# STM32WBA6M register map
File version: 1.0
CPU: CM33 r0p1, little endian, MPU, FPU, 4 interrupt priority bits
Registers are 32-bit, read-write, reset 0x0 unless marked. A register's access mark holds for its fields unless they carry their own. Offsets are from the block's base; [hi:lo] are bit positions; {n}, {i} and the like mark numbered series.

## GPIOB — GPIOB address block description
Base 0x42020400
Same registers: SEC_GPIOB 0x52020400
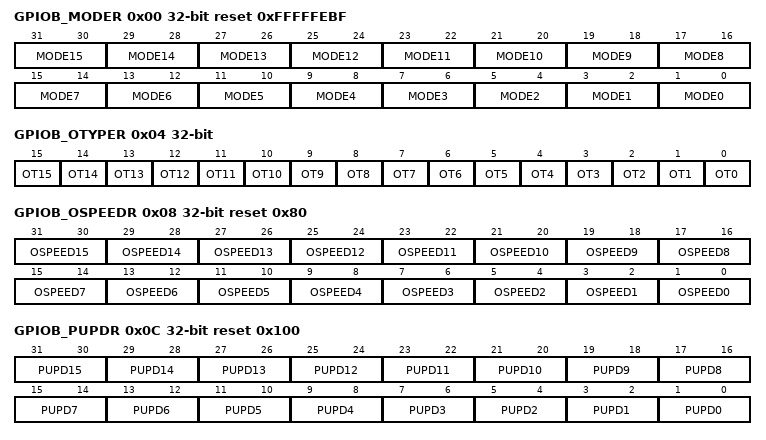
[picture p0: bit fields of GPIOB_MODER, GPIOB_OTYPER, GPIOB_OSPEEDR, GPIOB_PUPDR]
0x00 GPIOB_MODER reset 0xFFFFFEBF — GPIO port B mode register
  [31:30] MODE15 — Port configuration I/O pin 15
    0=Input mode; 1=General purpose output mode; 2=Alternate function mode; 3=Analog mode (reset state)
  [2n+1:2n] MODE{n} (n=0..14) — Port configuration I/O pin {n}
0x04 GPIOB_OTYPER — GPIO port B output type register
  [all] fields
    0=Output push-pull (reset state); 1=Output open-drain
  [n] OT{n} (n=0..15) — Port configuration I/O pin y
0x08 GPIOB_OSPEEDR reset 0x80 — GPIO port B output speed register
  [31:30] OSPEED15 — Port configuration I/O pin 15
    0=Low speed; 1=Medium speed; 2=High speed
  [2n+1:2n] OSPEED{n} (n=0..14) — Port configuration I/O pin {n}
0x0C GPIOB_PUPDR reset 0x100 — GPIO port B pull-up/pull-down register
  [31:30] PUPD15 — Port configuration I/O pin 15
    0=No pull-up, pull-down; 1=Pull-up; 2=Pull-down
  [2n+1:2n] PUPD{n} (n=0..14) — Port configuration I/O pin {n}
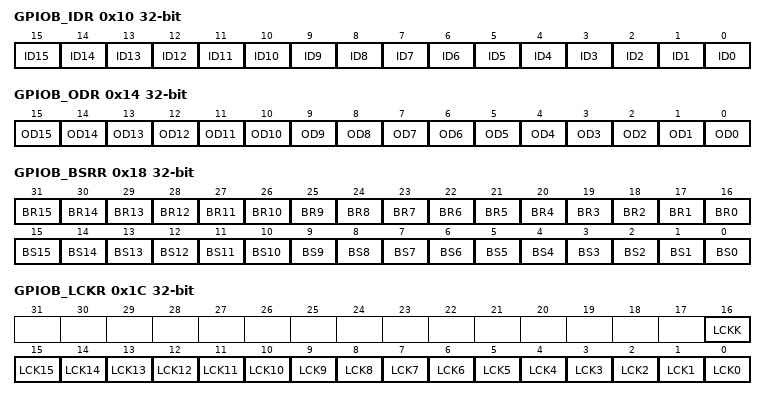
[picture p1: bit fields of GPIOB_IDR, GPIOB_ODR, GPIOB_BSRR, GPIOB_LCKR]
0x10 GPIOB_IDR ro (reset mask 0xFFFF0000) — GPIO port B input data register
  [n] ID{n} (n=0..15) — Port input data I/O pin y
0x14 GPIOB_ODR — GPIO port B output data register
  [n] OD{n} (n=0..15) — Port output data I/O pin y
0x18 GPIOB_BSRR wo — GPIO port B bit set/reset register
  [n+16] BR{n} (n=0..15) — Port reset I/O pin y
    0=No action on the corresponding ODy bit; 1=Resets the corresponding ODy bit
  [n] BS{n} (n=0..15) — Port set I/O pin y
    0=No action on the corresponding ODy bit; 1=Sets the corresponding ODy bit
0x1C GPIOB_LCKR — GPIO port B configuration lock register
  [16] LCKK — Lock key
    0=Port configuration lock key not active; 1=Port configuration lock key active
  [n] LCK{n} (n=0..15) — Port lock I/O pin y
    0=Port configuration not locked; 1=Port configuration locked
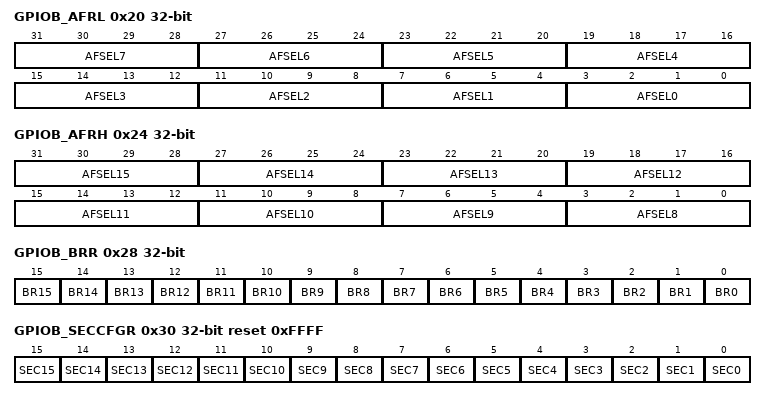
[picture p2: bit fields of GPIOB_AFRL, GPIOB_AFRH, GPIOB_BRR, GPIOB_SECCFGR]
0x20 GPIOB_AFRL — GPIO port B alternate function low register
  [31:28] AFSEL7 — Alternate function selection for port I/O pin 7
    {v}=AF{v} (v=0..15)
  [4n+3:4n] AFSEL{n} (n=0..6) — Alternate function selection for port I/O pin {n}
0x24 GPIOB_AFRH — GPIO port B alternate function high register
  [31:28] AFSEL15 — Alternate function selection for port I/O pin 15
    {v}=AF{v} (v=0..15)
  [4n-29:4n-32] AFSEL{n} (n=8..14) — Alternate function selection for port I/O pin {n}
0x28 GPIOB_BRR wo — GPIO port B bit reset register
  [all] fields
    0=No action on the corresponding ODy bit; 1=Reset the corresponding ODy bit
  [n] BR{n} (n=0..15) — Port reset I/O pin y
0x30 GPIOB_SECCFGR reset 0xFFFF — GPIO port B secure configuration register
  [all] fields
    0=The I/O pin is nonsecure; 1=The I/O pin is secure
  [n] SEC{n} (n=0..15) — I/O pin of port secure bit enable y

## GPIOC — GPIOC address block description
Base 0x42020800
Same registers: SEC_GPIOC 0x52020800
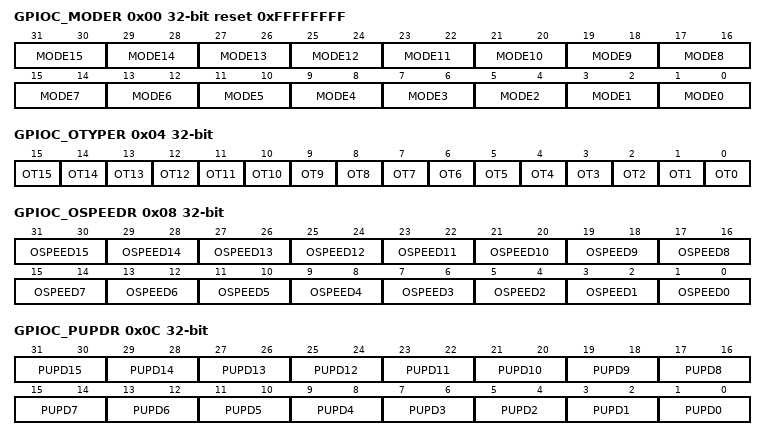
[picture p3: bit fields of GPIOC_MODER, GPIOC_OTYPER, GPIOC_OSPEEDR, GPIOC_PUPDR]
0x00 GPIOC_MODER reset 0xFFFFFFFF — GPIO port C mode register
  [31:30] MODE15 — Port configuration I/O pin 15
    0=Input mode; 1=General purpose output mode; 2=Alternate function mode; 3=Analog mode (reset state)
  [2n+1:2n] MODE{n} (n=0..14) — Port configuration I/O pin {n}
0x04 GPIOC_OTYPER — GPIO port C output type register
  [all] fields
    0=Output push-pull (reset state); 1=Output open-drain
  [n] OT{n} (n=0..15) — Port configuration I/O pin y
0x08 GPIOC_OSPEEDR — GPIO port C output speed register
  [31:30] OSPEED15 — Port configuration I/O pin 15
    0=Low speed; 1=Medium speed; 2=High speed
  [2n+1:2n] OSPEED{n} (n=0..14) — Port configuration I/O pin {n}
0x0C GPIOC_PUPDR — GPIO port C pull-up/pull-down register
  [31:30] PUPD15 — Port configuration I/O pin 15
    0=No pull-up, pull-down; 1=Pull-up; 2=Pull-down
  [2n+1:2n] PUPD{n} (n=0..14) — Port configuration I/O pin {n}
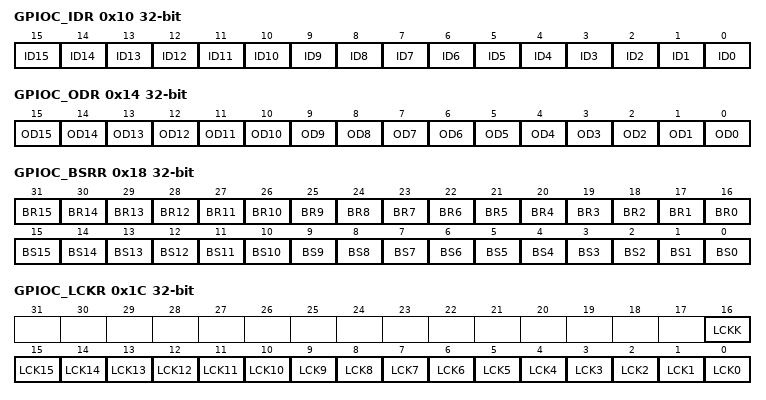
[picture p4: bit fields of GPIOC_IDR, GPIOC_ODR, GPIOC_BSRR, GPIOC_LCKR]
0x10 GPIOC_IDR ro (reset mask 0xFFFF0000) — GPIO port C input data register
  [n] ID{n} (n=0..15) — Port input data I/O pin y
0x14 GPIOC_ODR — GPIO port C output data register
  [n] OD{n} (n=0..15) — Port output data I/O pin y
0x18 GPIOC_BSRR wo — GPIO port C bit set/reset register
  [n+16] BR{n} (n=0..15) — Port reset I/O pin y
    0=No action on the corresponding ODy bit; 1=Resets the corresponding ODy bit
  [n] BS{n} (n=0..15) — Port set I/O pin y
    0=No action on the corresponding ODy bit; 1=Sets the corresponding ODy bit
0x1C GPIOC_LCKR — GPIO port C configuration lock register
  [16] LCKK — Lock key
    0=Port configuration lock key not active; 1=Port configuration lock key active
  [n] LCK{n} (n=0..15) — Port lock I/O pin y
    0=Port configuration not locked; 1=Port configuration locked
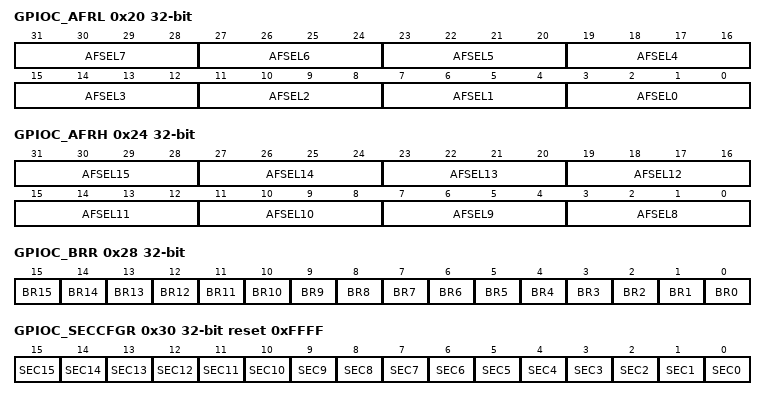
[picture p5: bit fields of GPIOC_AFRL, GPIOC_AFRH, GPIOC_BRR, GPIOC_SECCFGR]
0x20 GPIOC_AFRL — GPIO port C alternate function low register
  [31:28] AFSEL7 — Alternate function selection for port I/O pin 7
    {v}=AF{v} (v=0..15)
  [4n+3:4n] AFSEL{n} (n=0..6) — Alternate function selection for port I/O pin {n}
0x24 GPIOC_AFRH — GPIO port C alternate function high register
  [31:28] AFSEL15 — Alternate function selection for port I/O pin 15
    {v}=AF{v} (v=0..15)
  [4n-29:4n-32] AFSEL{n} (n=8..14) — Alternate function selection for port I/O pin {n}
0x28 GPIOC_BRR wo — GPIO port C bit reset register
  [all] fields
    0=No action on the corresponding ODy bit; 1=Reset the corresponding ODy bit
  [n] BR{n} (n=0..15) — Port reset I/O pin y
0x30 GPIOC_SECCFGR reset 0xFFFF — GPIO port C secure configuration register
  [all] fields
    0=The I/O pin is nonsecure; 1=The I/O pin is secure
  [n] SEC{n} (n=0..15) — I/O pin of port secure bit enable y

## Notices in the file
Copyright (c) 2025 STMicroelectronics.
SPDX-License-Identifier: Apache-2.0
Licensed under the Apache License, Version 2.0 (the "License");
you may not use this file except in compliance with the License.
You may obtain a copy of the License at
http://www.apache.org/licenses/LICENSE-2.0
Unless required by applicable law or agreed to in writing, software
distributed under the License is distributed on an "AS IS" BASIS,
WITHOUT WARRANTIES OR CONDITIONS OF ANY KIND, either express or implied.
See the License for the specific language governing permissions and
limitations under the License.
